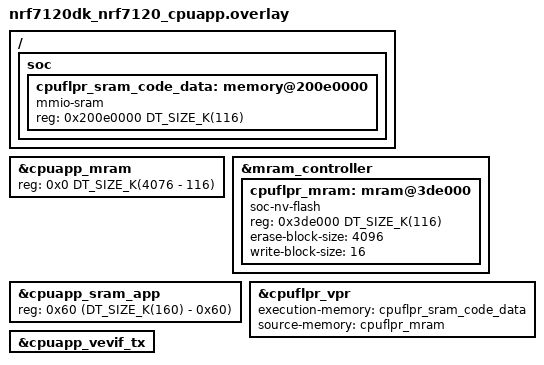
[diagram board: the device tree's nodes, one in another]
/*
 * Copyright (c) 2025 Nordic Semiconductor ASA
 *
 * SPDX-License-Identifier: LicenseRef-Nordic-5-Clause
 */

#include "app_aliases_common.dtsi"

/ {
	soc {
		cpuflpr_sram_code_data: memory@200e0000 {
			compatible = "mmio-sram";
			reg = <0x200e0000 DT_SIZE_K(116)>;
			ranges = <0x0 0x200e0000 DT_SIZE_K(116)>;
			#address-cells = <1>;
			#size-cells = <1>;
		};
	};
};

&cpuapp_mram {
	reg = <0x0 DT_SIZE_K(4076 - 116)>;
	ranges = <0x0 0x0 DT_SIZE_K(4076 - 116)>;

	/delete-node/ partitions;
};

&mram_controller {
	cpuflpr_mram: mram@3de000 {
		compatible = "soc-nv-flash";
		reg = <0x3de000 DT_SIZE_K(116)>;
		ranges = <0x0 0x3de000 DT_SIZE_K(116)>;
		erase-block-size = <4096>;
		write-block-size = <16>;
		#address-cells = <1>;
		#size-cells = <1>;
	};
};

&cpuapp_sram_app {
	reg = <0x60 (DT_SIZE_K(160) - 0x60)>;
};

&cpuflpr_vpr {
	execution-memory = <&cpuflpr_sram_code_data>;
	source-memory = <&cpuflpr_mram>;
	status = "okay";
};

&cpuapp_vevif_tx {
	status = "okay";
};

/* The same set of GPIO and GPIOTE DTS nodes are enabled in the cpuapp and the cpuflpr targets.
 * This is done to allow control over one Button and one LED in each core. The benchmark code is
 * responsible for ensuring that each core exclusively uses the individual GPIO pin and the GPIOTE
 * instance that may be used with the GPIO pin (Button).
 */

#define WITH_FLPR_PARTITIONS
#include <vendor/nordic/nrf7120_cpuapp_partition.dtsi>
